# RT58X register map
Series: ARMv8-M Mainline; File version: 1.0
CPU: CM3 r0p0, little endian, MPU, no FPU, VTOR, 3 interrupt priority bits
Registers are 32-bit, read-write, reset 0x0 unless marked. A register's access mark holds for its fields unless they carry their own. Offsets are from the block's base; [hi:lo] are bit positions.

## I2C_M — I2C_M Register block
Base 0xA0100000
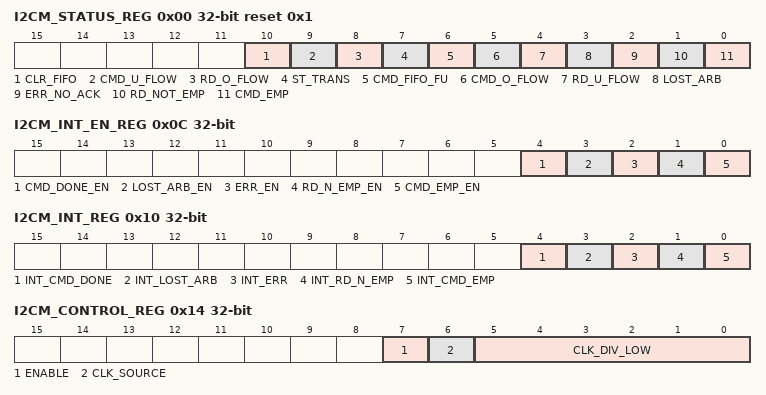
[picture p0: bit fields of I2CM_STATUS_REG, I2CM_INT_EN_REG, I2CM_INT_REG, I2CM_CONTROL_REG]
0x00 I2CM_STATUS_REG reset 0x1 — i2cm status
  [10] CLR_FIFO — Read: A value of 1 indicates that a FIFO Clear is in progress and is not yet complete. A value of 0 indicates that no FIFO Clear is in progress. Write: A value of 1 initiates a clear of both FIFOs (Command FIFO and Read Data FIFO). This self-clearing bit will be read as 0 again when the FIFO clear is complete.
    0=B_10 (Read: A value of 1 indicates that a FIFO Clear is in progress and is not yet complete. A value of 0 indicates that no FIFO Clear is in progress. Write: A value of 1 initiates a clear of both FIFOs (Command FIFO and Read Data FIFO). This self-clearing bit will be read as 0 again when the FIFO clear is complete.)
  [9] CMD_U_FLOW ro — A value of 1 indicates an Error Condition: Command FIFO Underflow.
    0=B_9 (A value of 1 indicates an Error Condition: Command FIFO Underflow.)
  [8] RD_O_FLOW ro — A value of 1 indicates an Error Condition: Read Data FIFO Overflow.
    0=B_8 (A value of 1 indicates an Error Condition: Read Data FIFO Overflow.)
  [7] ST_TRANS ro — A value of 1 indicates Transfer In Progress.
    0=B_7 (A value of 1 indicates Transfer In Progress.)
  [6] CMD_FIFO_FU ro — A value of 1 indicates Command FIFO Full.
    0=B_6 (A value of 1 indicates Command FIFO Full.)
  [5] CMD_O_FLOW ro — A value of 1 indicates an Error Condition: Command FIFO Overflow.
    0=B_5 (A value of 1 indicates an Error Condition: Command FIFO Overflow.)
  [4] RD_U_FLOW ro — A value of 1 indicates an Error Condition: Read Data FIFO Underflow.
    0=B_4 (A value of 1 indicates an Error Condition: Read Data FIFO Underflow.)
  [3] LOST_ARB — Read (Status): A value of 1 indicates that the Master has lost arbitration. Write (Clear): A value of 1 clears this condition on the i2c clock domain.
    0=B_3 (Read (Status): A value of 1 indicates that the Master has lost arbitration. Write (Clear): A value of 1 clears this condition on the i2c clock domain.)
  [2] ERR_NO_ACK — Read (Status): A value of 1 indicates an Error Condition: I2C Protocol Error. This signifies that no I2C “ACK” was detected from slave when expected. Write (Clear): A value of 1 clears this condition on the i2c clock domain.
    0=B_2 (Read (Status): A value of 1 indicates an Error Condition: I2C Protocol Error. This signifies that no I2C “ACK” was detected from slave when expected. Write (Clear): A value of 1 clears this condition on the i2c clock domain.)
  [1] RD_NOT_EMP ro — A value of 1 indicates Read Data FIFO Not Empty.
    0=B_1 (A value of 1 indicates Read Data FIFO Not Empty.)
  [0] CMD_EMP ro — A value of 1 indicates Command FIFO Empty.
    0=B_0 (A value of 1 indicates Command FIFO Empty.)
0x04 I2CM_READ_DATA_REG ro — i2cm read data
  [7:0] READ_DATA — Data from I2C Slave to be read by processor.
    0=B_0_to_7 (Data from I2C Slave to be read by processor.)
0x08 I2CM_CMD_REG — i2cm cmd
  [7:0] CMD wo — Commands from processor to be implemented as I2C events. Writes to this register go directly into the Command FIFO. If a FIFO clear is in progress, writes to the Command FIFO are inhibited.
    0=B_0_to_7 (Commands from processor to be implemented as I2C events. Writes to this register go directly into the Command FIFO. If a FIFO clear is in progress, writes to the Command FIFO are inhibited.)
0x0C I2CM_INT_EN_REG — i2cm int en
  [4] CMD_DONE_EN — Enable Command FIFO Done Interrupt (1=Enable, 0=Disable).
    0=B_4 (Enable Command FIFO Done Interrupt (1=Enable, 0=Disable).)
  [3] LOST_ARB_EN — Enable Loss of Arbitration Interrupt (1=Enable, 0=Disable).
    0=B_3 (Enable Loss of Arbitration Interrupt (1=Enable, 0=Disable).)
  [2] ERR_EN — Enable Error Interrupt (1=Enable, 0=Disable).
    0=B_2 (Enable Error Interrupt (1=Enable, 0=Disable).)
  [1] RD_N_EMP_EN — Enable Read Data FIFO Not Empty Interrupt (1=Enable, 0=Disable).
    0=B_1 (Enable Read Data FIFO Not Empty Interrupt (1=Enable, 0=Disable).)
  [0] CMD_EMP_EN — Enable Command FIFO Empty Interrupt (1=Enable, 0=Disable).
    0=B_0 (Enable Command FIFO Empty Interrupt (1=Enable, 0=Disable).)
0x10 I2CM_INT_REG — i2cm int
  [4] INT_CMD_DONE — Read (Status) - a value of 1 indicates Command FIFO Done Interrupt is active. Write (Clear) - a value of 1 clears the Command FIFO Done Interrupt.
    0=B_4 (Read (Status) - a value of 1 indicates Command FIFO Done Interrupt is active. Write (Clear) - a value of 1 clears the Command FIFO Done Interrupt.)
  [3] INT_LOST_ARB — Read (Status) - a value of 1 indicates Loss of Arbitration Interrupt is active. Write (Clear) - a value of 1 clears the Loss of Arbitration Interrupt.
    0=B_3 (Read (Status) - a value of 1 indicates Loss of Arbitration Interrupt is active. Write (Clear) - a value of 1 clears the Loss of Arbitration Interrupt.)
  [2] INT_ERR — Read (Status) - a value of 1 indicates Error Interrupt is active. Write (Clear) - a value of 1 clears the Error Interrupt.
    0=B_2 (Read (Status) - a value of 1 indicates Error Interrupt is active. Write (Clear) - a value of 1 clears the Error Interrupt.)
  [1] INT_RD_N_EMP — Read (Status) - a value of 1 indicates Read Data FIFO Not Empty Interrupt is active. Write (Clear) - a value of 1 clears the Read Data FIFO Not Empty Interrupt.
    0=B_1 (Read (Status) - a value of 1 indicates Read Data FIFO Not Empty Interrupt is active. Write (Clear) - a value of 1 clears the Read Data FIFO Not Empty Interrupt.)
  [0] INT_CMD_EMP — Read (Status) - a value of 1 indicates Command FIFO Empty Interrupt is active. Write (Clear) - a value of 1 clears the Command FIFO Empty Interrup.
    0=B_0 (Read (Status) - a value of 1 indicates Command FIFO Empty Interrupt is active. Write (Clear) - a value of 1 clears the Command FIFO Empty Interrup.)
0x14 I2CM_CONTROL_REG — i2cm control
  [7] ENABLE — I2C Enable. (1=Enable, 0=Disable)
    0=B_7 (I2C Enable. (1=Enable, 0=Disable))
  [6] CLK_SOURCE — I2C Clock Source. (1 = PCLK, 0 = clkI2C)
    0=B_6 (I2C Clock Source. (1 = PCLK, 0 = clkI2C))
  [5:0] CLK_DIV_LOW — I2C Clock Divider. (Lower 6 bits)
    0=B_0_to_5 (I2C Clock Divider. (Lower 6 bits))
0x18 I2CM_PRESCALE_REG — i2cm prescale
  [7:0] CLK_DIV_HIGH — I2C Clock Divider. (Upper 8 bits) Note that the entire clock divider is 14 bits.
    0=B_0_to_7 (I2C Clock Divider. (Upper 8 bits) Note that the entire clock divider is 14 bits.)
